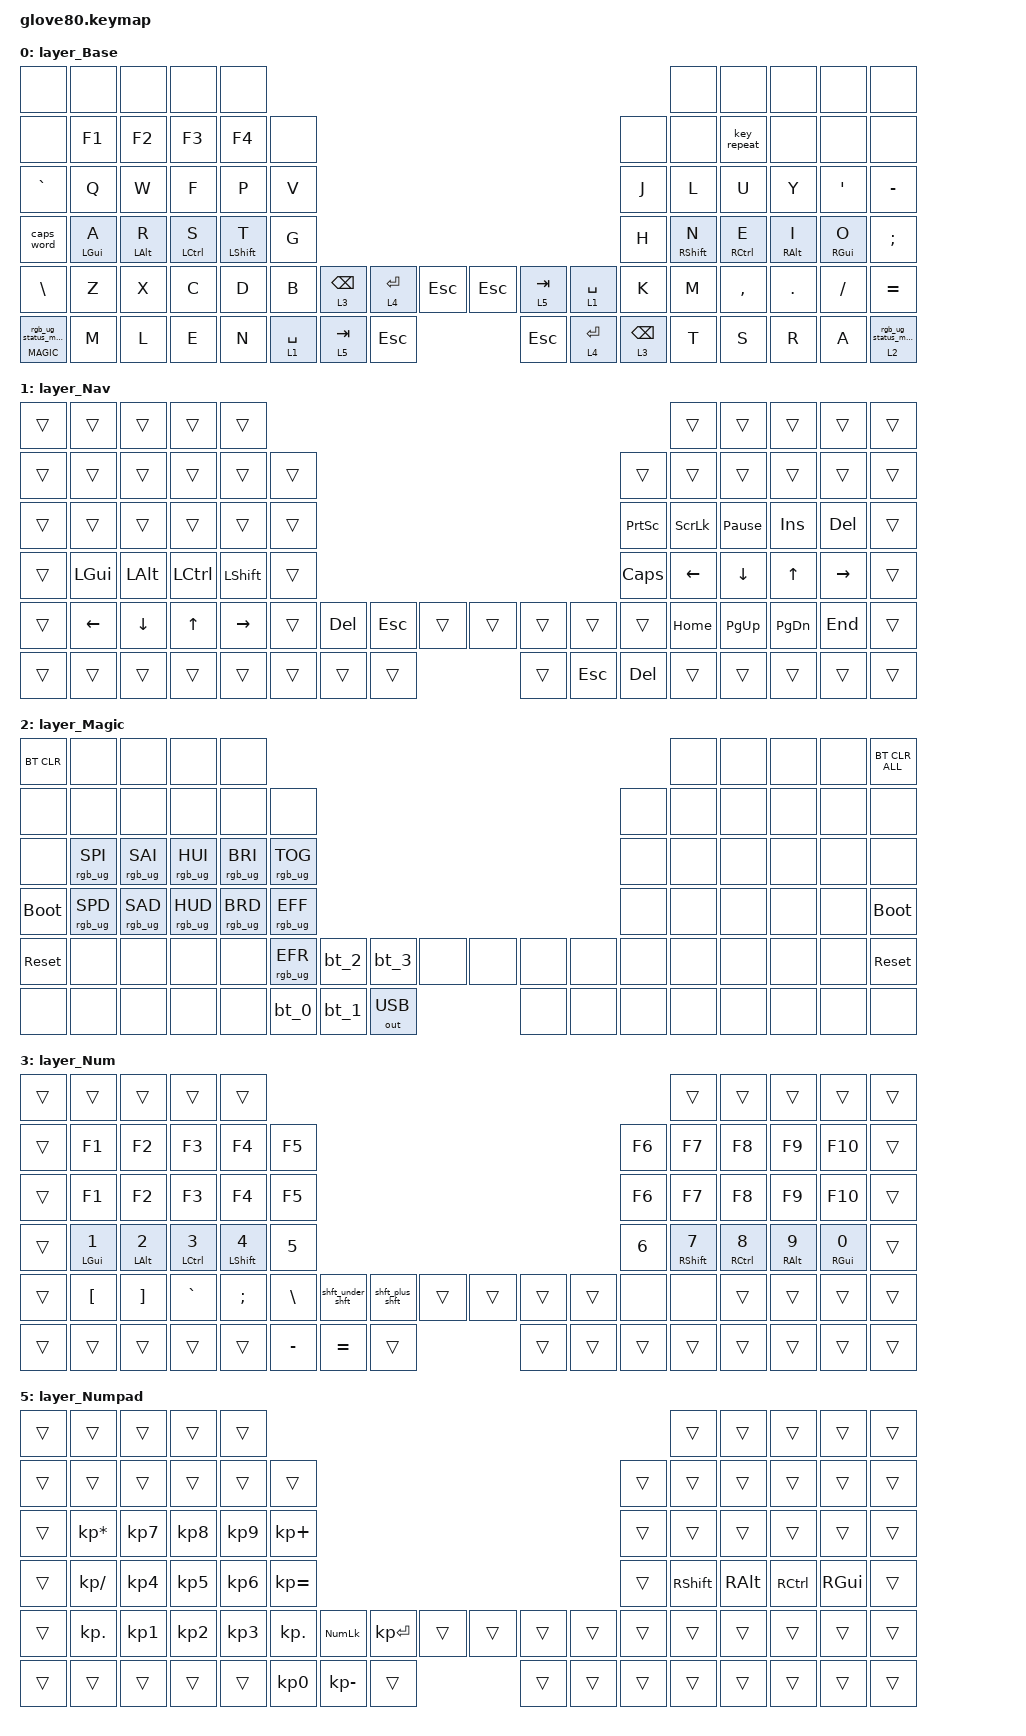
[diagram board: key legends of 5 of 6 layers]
/*
 * Copyright (c) 2020 The ZMK Contributors
 * Copyright (c) 2022 Innaworks Development Limited, trading as MoErgo
 *
 * SPDX-License-Identifier: MIT
 */

#include <behaviors.dtsi>
#include <dt-bindings/zmk/keys.h>
#include <dt-bindings/zmk/bt.h>
#include <dt-bindings/zmk/ext_power.h>
#include <dt-bindings/zmk/outputs.h>
#include <dt-bindings/zmk/rgb.h>

#define HYPER LC(LS(LG(LALT)))

// layers
#define DEFAULT 0
#define LOWER 1
#define MAGIC 2

/ {
    /**************************************************************************
     * Glove80 system behavior & macros                                       *
     **************************************************************************/
    behaviors {
        // ----------------------------------------
        // MoErgo's custom behaviors
        //
        // For the "layer" key, it'd nice to be able to use it as either a shift or a toggle.
        // Configure it as a tap dance, so the first tap (or hold) is a &mo and the second tap is a &to
        layer_td: tap_dance_0 {
            compatible = "zmk,behavior-tap-dance";
            label = "LAYER_TAP_DANCE";
            #binding-cells = <0>;
            tapping-term-ms = <200>;
            bindings = <&mo LOWER>, <&to LOWER>;
        };
        magic: magic_hold_tap {
            compatible = "zmk,behavior-hold-tap";
            label = "MAGIC_HOLD_TAP";
            #binding-cells = <2>;
            flavor = "tap-preferred";
            tapping-term-ms = <200>;
            bindings = <&mo>, <&rgb_ug_status_macro>;
        };

        // ----------------------------------------
        // My custom behaviors
        //
        my_ht: my_hold_tap {
            compatible = "zmk,behavior-hold-tap";
            label = "MY_HOLD_TAP";
            #binding-cells = <2>;
            flavor = "balanced";
            tapping-term-ms = <200>;
            require-prior-idle-ms = <150>;
            quick-tap-ms = <100>;
            bindings = <&kp>, <&kp>;
        };
        my_shft_ht: my_shift_hold_tap {
            compatible = "zmk,behavior-hold-tap";
            label = "MY_SHIFT_HOLD_TAP";
            #binding-cells = <2>;
            flavor = "balanced";
            tapping-term-ms = <125>;
            bindings = <&kp>, <&kp>;
        };
        my_lt: my_layer_tap {
            compatible = "zmk,behavior-hold-tap";
            #binding-cells = <2>;
            flavor = "balanced";
            tapping-term-ms = <150>;
            quick-tap-ms = <50>;
            bindings = <&mo>, <&kp>;
            display-name = "Layer-Tap";
        };
        // // modded_ht: modded_hold_tap {
        // //     compatible = "zmk,behavior-modded-hold-tap";
        // //     label = "MODDED_HT";
        // //     #binding-cells = <3>;
        // //     tapping-term-ms = <200>;
        // //     flavor = "balanced";
        // // };
    };

    macros {
        // ----------------------------------------
        // MoErgo's custom macros
        //
        rgb_ug_status_macro: rgb_ug_status_macro_0 {
            label = "RGB_UG_STATUS";
            compatible = "zmk,behavior-macro";
            #binding-cells = <0>;
            bindings
                = <&rgb_ug RGB_STATUS>;
        };
        bt_0: bt_profile_macro_0 {
            label = "BT_0";
            compatible = "zmk,behavior-macro";
            #binding-cells = <0>;
            bindings
                = <&out OUT_BLE>,
                  <&bt BT_SEL 0>;
        };
        bt_1: bt_profile_macro_1 {
            label = "BT_1";
            compatible = "zmk,behavior-macro";
            #binding-cells = <0>;
            bindings
                = <&out OUT_BLE>,
                  <&bt BT_SEL 1>;
        };
        bt_2: bt_profile_macro_2 {
            label = "BT_2";
            compatible = "zmk,behavior-macro";
            #binding-cells = <0>;
            bindings
                = <&out OUT_BLE>,
                  <&bt BT_SEL 2>;
        };
        bt_3: bt_profile_macro_3 {
            label = "BT_3";
            compatible = "zmk,behavior-macro";
            #binding-cells = <0>;
            bindings
                = <&out OUT_BLE>,
                  <&bt BT_SEL 3>;
        };
        
        // ----------------------------------------
        // My custom macros
        //
        ps_m: powershell_macro {
            label = "POWERSHELL_MACRO";
            compatible = "zmk,behavior-macro";
            wait-ms = <10>;
            tap-ms = <10>;
            #binding-cells = <0>;
            bindings
                = <&macro_tap &kp P>
                , <&macro_tap &kp O>
                , <&macro_tap &kp W>
                , <&macro_tap &kp E>
                , <&macro_tap &kp R>
                , <&macro_tap &kp S>
                , <&macro_tap &kp H>
                , <&macro_tap &kp E>
                , <&macro_tap &kp L>
                , <&macro_tap &kp L>
                ;
        };
        rgb_mo_1: rgb_mo_1 {
            label = "RGB_MO_1";
            compatible = "zmk,behavior-macro";
            #binding-cells = <0>;
            wait-ms = <0>;
            tap-ms = <0>;
            bindings
                = <&macro_press &mo 1>
                , <&macro_tap &rgb_ug RGB_COLOR_HSB(128,100,100)>
                , <&macro_pause_for_release>
                , <&macro_release &mo 1>
                // , <&macro_tap &rgb_ug RGB_COLOR_HSB(300,100,50)>;
                , <&macro_tap &rgb_ug RGB_COLOR_HSB(0,0,0)>;
        };
        
        // Custom "shifted" symbols macros
        shft_excl_shft: shft_excl_shft {
            label = "Shifted Tap excl";
            compatible = "zmk,behavior-macro";
            #binding-cells = <0>;
            bindings
                = <&macro_press &kp LSFT>
                , <&macro_tap &kp N1>
                , <&macro_release &kp LSFT>
                ;
        };

        shft_at_shft: shft_at_shft {
            label = "Shifted Tap at";
            compatible = "zmk,behavior-macro";
            #binding-cells = <0>;
            bindings
                = <&macro_press &kp LSFT>
                , <&macro_tap &kp N2>
                , <&macro_release &kp LSFT>
                ;
        };

        shft_hash_shft: shft_hash_shft {
            label = "Shifted Tap hash";
            compatible = "zmk,behavior-macro";
            #binding-cells = <0>;
            bindings
                = <&macro_press &kp LSFT>
                , <&macro_tap &kp N3>
                , <&macro_release &kp LSFT>
                ;
        };

        shft_dllr_shft: shft_dllr_shft {
            label = "Shifted Tap dollar";
            compatible = "zmk,behavior-macro";
            #binding-cells = <0>;
            bindings
                = <&macro_press &kp LSFT>
                , <&macro_tap &kp N4>
                , <&macro_release &kp LSFT>
                ;
        };

        shft_pcnt_shft: shft_pcnt_shft {
            label = "Shifted Tap percent";
            compatible = "zmk,behavior-macro";
            #binding-cells = <0>;
            bindings
                = <&macro_press &kp LSFT>
                , <&macro_tap &kp N5>
                , <&macro_release &kp LSFT>
                ;
        };

        shft_caret_shft: shft_caret_shft {
            label = "Shifted Tap caret";
            compatible = "zmk,behavior-macro";
            #binding-cells = <0>;
            bindings
                = <&macro_press &kp LSFT>
                , <&macro_tap &kp N6>
                , <&macro_release &kp LSFT>
                ;
        };

        shft_amp_shft: shft_amp_shft {
            label = "Shifted Tap ampersand";
            compatible = "zmk,behavior-macro";
            #binding-cells = <0>;
            bindings
                = <&macro_press &kp LSFT>
                , <&macro_tap &kp N7>
                , <&macro_release &kp LSFT>
                ;
        };

        shft_astrk_shft: shft_astrk_shft {
            label = "Shifted Tap asterisk";
            compatible = "zmk,behavior-macro";
            #binding-cells = <0>;
            bindings
                = <&macro_press &kp LSFT>
                , <&macro_tap &kp N8>
                , <&macro_release &kp LSFT>
                ;
        };

        shft_lpar_shft: shft_lpar_shft {
            label = "Shifted Tap left parenthesis";
            compatible = "zmk,behavior-macro";
            #binding-cells = <0>;
            bindings
                = <&macro_press &kp LSFT>
                , <&macro_tap &kp N9>
                , <&macro_release &kp LSFT>
                ;
        };

        shft_rpar_shft: shft_rpar_shft {
            label = "Shifted Tap right parenthesis";
            compatible = "zmk,behavior-macro";
            #binding-cells = <0>;
            bindings
                = <&macro_press &kp LSFT>
                , <&macro_tap &kp N0>
                , <&macro_release &kp LSFT>
                ;
        };

        shft_under_shft: shft_under_shft {
            label = "Shifted Tap underscore";
            compatible = "zmk,behavior-macro";
            #binding-cells = <0>;
            bindings
                = <&macro_press &kp LSFT>
                , <&macro_tap &kp MINUS>
                , <&macro_release &kp LSFT>
                ;
        };

        shft_plus_shft: shft_plus_shft {
            label = "Shifted Tap plus";
            compatible = "zmk,behavior-macro";
            #binding-cells = <0>;
            bindings
                = <&macro_press &kp LSFT>
                , <&macro_tap &kp EQUAL>
                , <&macro_release &kp LSFT>
                ;
        };

        shft_lthan_shft: shft_lthan_shft {
            label = "Shifted Tap less-than symbol";
            compatible = "zmk,behavior-macro";
            #binding-cells = <0>;
            bindings
                = <&macro_press &kp LSFT>
                , <&macro_tap &kp COMMA>
                , <&macro_release &kp LSFT>
                ;
        };

        shft_gthan_shft: shft_gthan_shft {
            label = "Shifted Tap greater-than symbol";
            compatible = "zmk,behavior-macro";
            #binding-cells = <0>;
            bindings
                = <&macro_press &kp LSFT>
                , <&macro_tap &kp DOT>
                , <&macro_release &kp LSFT>
                ;
        };

        shft_qmark_shft: shft_qmark_shft {
            label = "Shifted Tap qustion mark";
            compatible = "zmk,behavior-macro";
            #binding-cells = <0>;
            bindings
                = <&macro_press &kp LSFT>
                , <&macro_tap &kp SLASH>
                , <&macro_release &kp LSFT>
                ;
        };

        shft_dqt_shft: shft_dqt_shft {
            label = "Shifted Tap double-quote";
            compatible = "zmk,behavior-macro";
            #binding-cells = <0>;
            bindings
                = <&macro_press &kp LSFT>
                , <&macro_tap &kp SQT>
                , <&macro_release &kp LSFT>
                ;
        };

        shft_pipe_shft: shft_pipe_shft {
            label = "Shifted Tap pipe";
            compatible = "zmk,behavior-macro";
            #binding-cells = <0>;
            bindings
                = <&macro_press &kp LSFT>
                , <&macro_tap &kp BSLH>
                , <&macro_release &kp LSFT>
                ;
        };

        shft_colon_shft: shft_colon_shft {
            label = "Shifted Tap colon";
            compatible = "zmk,behavior-macro";
            #binding-cells = <0>;
            bindings
                = <&macro_press &kp LSFT>
                , <&macro_tap &kp SEMI>
                , <&macro_release &kp LSFT>
                ;
        };

        shft_tilde_shft: shft_tilde_shft {
            label = "Shifted Tap tilde";
            compatible = "zmk,behavior-macro";
            #binding-cells = <0>;
            bindings
                = <&macro_press &kp LSFT>
                , <&macro_tap &kp GRAVE>
                , <&macro_release &kp LSFT>
                ;
        };

        shft_rbrc_shft: shft_rbrc_shft {
            label = "Shifted Tap right-brace";
            compatible = "zmk,behavior-macro";
            #binding-cells = <0>;
            bindings
                = <&macro_press &kp LSFT>
                , <&macro_tap &kp RBKT>
                , <&macro_release &kp LSFT>
                ;
        };

        shft_lbrc_shft: shft_lbrc_shft {
            label = "Shifted Tap left-brace";
            compatible = "zmk,behavior-macro";
            #binding-cells = <0>;
            bindings
                = <&macro_press &kp LSFT>
                , <&macro_tap &kp LBKT>
                , <&macro_release &kp LSFT>
                ;
        };
    };

    keymap {
        compatible = "zmk,keymap";

        layer_Base {
            bindings = <
 &none           &none          &none          &none           &none                                                                                                                                  &none           &none          &none          &none       &none
 &none           &kp F1         &kp F2         &kp F3          &kp F4               &none                                                                                      &none                  &none     &key_repeat          &none          &none       &none
 &kp GRAVE       &kp Q          &kp W          &kp F           &kp P                &kp V                                                                                      &kp J                  &kp L           &kp U          &kp Y        &kp SQT   &kp MINUS
 &caps_word      &my_ht LGUI A  &my_ht LALT R  &my_ht LCTRL S  &my_shft_ht LSHFT T  &kp G                                                                                      &kp H    &my_shft_ht RSHFT N  &my_ht RCTRL E  &my_ht RALT I  &my_ht RGUI O    &kp SEMI
 &kp BSLH        &kp Z          &kp X          &kp C           &kp D                &kp B  &my_lt 3 BSPC   &my_lt 4 RET  &kp ESC        &kp ESC  &my_lt 5 TAB  &my_lt 1 SPACE  &kp K                  &kp M       &kp COMMA        &kp DOT       &kp FSLH   &kp EQUAL
 &magic MAGIC 0  &kp M          &kp L          &kp E           &kp N                       &my_lt 1 SPACE  &my_lt 5 TAB  &kp ESC        &kp ESC  &my_lt 4 RET  &my_lt 3 BSPC                          &kp T           &kp S          &kp R          &kp A  &magic 2 0
            >;
        };

        layer_Nav {
            bindings = <
 &trans  &trans    &trans    &trans     &trans                                                                                   &trans           &trans     &trans     &trans  &trans
 &trans  &trans    &trans    &trans     &trans     &trans                                                              &trans    &trans           &trans     &trans     &trans  &trans
 &trans  &trans    &trans    &trans     &trans     &trans                                                           &kp PSCRN  &kp SLCK  &kp PAUSE_BREAK    &kp INS    &kp DEL  &trans
 &trans  &kp LGUI  &kp LALT  &kp LCTRL  &kp LSHFT  &trans                                                            &kp CAPS  &kp LEFT         &kp DOWN     &kp UP  &kp RIGHT  &trans
 &trans  &kp LEFT  &kp DOWN  &kp UP     &kp RIGHT  &trans    &kp DEL  &kp ESC  &trans        &trans   &trans   &trans  &trans  &kp HOME        &kp PG_UP  &kp PG_DN    &kp END  &trans
 &trans  &trans    &trans    &trans     &trans               &trans   &trans   &trans        &trans  &kp ESC  &kp DEL            &trans           &trans     &trans     &trans  &trans
            >;
        };

        layer_Magic {
            bindings = <
 &bt BT_CLR   &none            &none            &none            &none                                                                                       &none   &none   &none   &none  &bt BT_CLR_ALL
 &none        &none            &none            &none            &none            &none                                                              &none   &none   &none   &none   &none           &none
 &none        &rgb_ug RGB_SPI  &rgb_ug RGB_SAI  &rgb_ug RGB_HUI  &rgb_ug RGB_BRI  &rgb_ug RGB_TOG                                                    &none   &none   &none   &none   &none           &none
 &bootloader  &rgb_ug RGB_SPD  &rgb_ug RGB_SAD  &rgb_ug RGB_HUD  &rgb_ug RGB_BRD  &rgb_ug RGB_EFF                                                    &none   &none   &none   &none   &none     &bootloader
 &sys_reset   &none            &none            &none            &none            &rgb_ug RGB_EFR  &bt_2  &bt_3  &none         &none  &none  &none   &none   &none   &none   &none   &none      &sys_reset
 &none        &none            &none            &none            &none                             &bt_0  &bt_1  &out OUT_USB  &none  &none  &none           &none   &none   &none   &none           &none
            >;
        };

        layer_Num {
            bindings = <
 &trans  &trans          &trans          &trans           &trans                                                                                                           &trans           &trans          &trans          &trans  &trans
 &trans  &kp F1          &kp F2          &kp F3           &kp F4           &kp F5                                                                         &kp F6           &kp F7           &kp F8          &kp F9         &kp F10  &trans
 &trans  &kp F1          &kp F2          &kp F3           &kp F4           &kp F5                                                                         &kp F6           &kp F7           &kp F8          &kp F9         &kp F10  &trans
 &trans  &my_ht LGUI N1  &my_ht LALT N2  &my_ht LCTRL N3  &my_ht LSHFT N4  &kp N5                                                                         &kp N6  &my_ht RSHFT N7  &my_ht RCTRL N8  &my_ht RALT N9  &my_ht RGUI N0  &trans
 &trans  &kp LBKT        &kp RBKT        &kp GRAVE        &kp SEMI         &kp BSLH  &shft_under_shft  &shft_plus_shft  &trans    &trans  &trans  &trans   &none            &none           &trans          &trans          &trans  &trans
 &trans  &trans          &trans          &trans           &trans                     &kp MINUS         &kp EQUAL        &trans    &trans  &trans  &trans                   &trans           &trans          &trans          &trans  &trans
            >;
        };

        layer_Sym {
            bindings = <
 &trans  &trans           &trans           &trans            &trans                                                                                                                            &trans            &trans            &trans            &trans  &trans
 &none   &none            &none            &none             &none             &none                                                                                            &none           &none             &none             &none             &none   &none
 &trans  &kp F11          &kp F12          &kp F13           &kp F14           &kp F15                                                                                        &kp F16         &kp F17           &kp F18           &kp F19           &kp F20  &trans
 &trans  &shft_excl_shft  &shft_at_shft    &shft_hash_shft   &shft_dllr_shft   &shft_pcnt_shft                                                                       &shft_caret_shft  &shft_amp_shft  &shft_astrk_shft   &shft_lpar_shft   &shft_rpar_shft  &trans
 &trans  &shft_lbrc_shft  &shft_rbrc_shft  &shft_tilde_shft  &shft_colon_shft  &shft_pipe_shft  &trans            &trans           &trans    &trans  &trans  &trans             &none          &trans  &shft_lthan_shft  &shft_gthan_shft  &shft_qmark_shft  &trans
 &trans  &trans           &trans           &trans            &trans                             &shft_under_shft  &shft_plus_shft  &trans    &trans  &trans  &trans                                              &trans            &trans            &trans  &trans
            >;
        };

        layer_Numpad {
            bindings = <
 &trans  &trans           &trans     &trans     &trans                                                                                              &trans    &trans     &trans    &trans  &trans
 &trans  &trans           &trans     &trans     &trans     &trans                                                                        &trans     &trans    &trans     &trans    &trans  &trans
 &trans  &kp KP_MULTIPLY  &kp KP_N7  &kp KP_N8  &kp KP_N9  &kp KP_PLUS                                                                   &trans     &trans    &trans     &trans    &trans  &trans
 &trans  &kp KP_SLASH     &kp KP_N4  &kp KP_N5  &kp KP_N6  &kp KP_EQUAL                                                                  &trans  &kp RSHFT  &kp RALT  &kp RCTRL  &kp RGUI  &trans
 &trans  &kp KP_DOT       &kp KP_N1  &kp KP_N2  &kp KP_N3  &kp KP_DOT    &kp KP_NUM  &kp KP_ENTER  &trans        &trans  &trans  &trans  &trans     &trans    &trans     &trans    &trans  &trans
 &trans  &trans           &trans     &trans     &trans                   &kp KP_N0   &kp KP_MINUS  &trans        &trans  &trans  &trans             &trans    &trans     &trans    &trans  &trans
            >;
        };
    };
};
